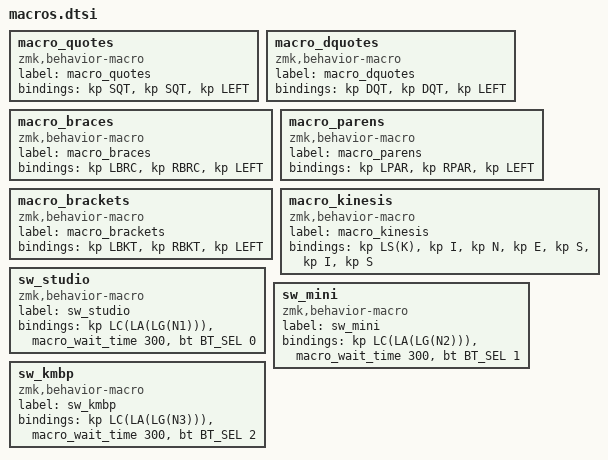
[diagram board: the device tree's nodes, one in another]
macro_quotes: macro_quotes{
compatible = "zmk,behavior-macro";
label = "macro_quotes";
#binding-cells = <0>;
bindings = <&kp SQT>, <&kp SQT>, <&kp LEFT>;
};
macro_dquotes: macro_dquotes{
compatible = "zmk,behavior-macro";
label = "macro_dquotes";
#binding-cells = <0>;
bindings = <&kp DQT>, <&kp DQT>, <&kp LEFT>;
};
macro_braces: macro_braces{
compatible = "zmk,behavior-macro";
label = "macro_braces";
#binding-cells = <0>;
bindings = <&kp LBRC>, <&kp RBRC>, <&kp LEFT>;
};
macro_parens: macro_parens{
compatible = "zmk,behavior-macro";
label = "macro_parens";
#binding-cells = <0>;
bindings = <&kp LPAR>, <&kp RPAR>, <&kp LEFT>;
};
macro_brackets: macro_brackets{
compatible = "zmk,behavior-macro";
label = "macro_brackets";
#binding-cells = <0>;
bindings = <&kp LBKT>, <&kp RBKT>, <&kp LEFT>;
};
macro_kinesis: macro_kinesis{
compatible = "zmk,behavior-macro";
label = "macro_kinesis";
#binding-cells = <0>;
bindings = <&kp LS(K)>, <&kp I>, <&kp N>, <&kp E>, <&kp S>, <&kp I>, <&kp S>;
};
/* Computer switch: send the Dell input-switch hotkey to the machine
 * being left (it still owns the DDC path), pause so the HID report
 * gets out over BT, then hop profile. Hotkeys are Ctrl+Opt+Cmd+1/2/3
 * mapped in BetterDisplay on all three machines. */
sw_studio: sw_studio{
compatible = "zmk,behavior-macro";
label = "sw_studio";
#binding-cells = <0>;
bindings = <&kp LC(LA(LG(N1)))>, <&macro_wait_time 300>, <&bt BT_SEL 0>;
};
sw_mini: sw_mini{
compatible = "zmk,behavior-macro";
label = "sw_mini";
#binding-cells = <0>;
bindings = <&kp LC(LA(LG(N2)))>, <&macro_wait_time 300>, <&bt BT_SEL 1>;
};
sw_kmbp: sw_kmbp{
compatible = "zmk,behavior-macro";
label = "sw_kmbp";
#binding-cells = <0>;
bindings = <&kp LC(LA(LG(N3)))>, <&macro_wait_time 300>, <&bt BT_SEL 2>;
};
